# STM32U585 register map
File version: 1.4
CPU: CM33 r0p1, little endian, MPU, FPU, 4 interrupt priority bits
Registers are 32-bit, read-write, reset 0x0 unless marked. A register's access mark holds for its fields unless they carry their own. Offsets are from the block's base; [hi:lo] are bit positions.

## GTZC2_TZSC
Base 0x46023000
Same registers: SEC_GTZC2_TZSC 0x56023000
0x00 TZSC_CR — TZSC control register
  [0] LCK — lock the configuration of GTZC1_TZSC_SECCFGRx and GTZC1_TZSC_PRIVCFGRx registers until next reset
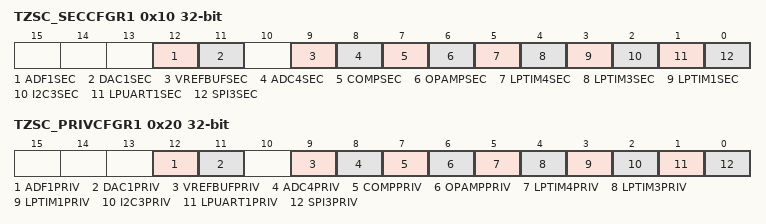
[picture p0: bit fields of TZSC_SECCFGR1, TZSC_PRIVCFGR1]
0x10 TZSC_SECCFGR1 — TZSC secure configuration register 1
  [12] ADF1SEC — secure access mode for ADF1
  [11] DAC1SEC — secure access mode for DAC1
  [9] VREFBUFSEC — secure access mode for VREFBUF
  [8] ADC4SEC — secure access mode for ADC4
  [7] COMPSEC — secure access mode for COMP
  [6] OPAMPSEC — secure access mode for OPAMP
  [5] LPTIM4SEC — secure access mode for LPTIM4
  [4] LPTIM3SEC — secure access mode for LPTIM3
  [3] LPTIM1SEC — secure access mode for LPTIM1
  [2] I2C3SEC — secure access mode for I2C3
  [1] LPUART1SEC — secure access mode for LPUART1
  [0] SPI3SEC — secure access mode for SPI3
0x20 TZSC_PRIVCFGR1 — TZSC privilege configuration register 1
  [12] ADF1PRIV — privileged access mode for ADF1
  [11] DAC1PRIV — privileged access mode for DAC1
  [9] VREFBUFPRIV — privileged access mode for VREFBUF
  [8] ADC4PRIV — privileged access mode for ADC4
  [7] COMPPRIV — privileged access mode for COMP
  [6] OPAMPPRIV — privileged access mode for OPAMP
  [5] LPTIM4PRIV — privileged access mode for LPTIM4
  [4] LPTIM3PRIV — privileged access mode for LPTIM3
  [3] LPTIM1PRIV — privileged access mode for LPTIM1
  [2] I2C3PRIV — privileged access mode for I2C3
  [1] LPUART1PRIV — privileged access mode for LPUART1
  [0] SPI3PRIV — privileged access mode for SPI3

## TIM6 — General-purpose-timers
Base 0x40001000
Same registers: TIM7 0x40001400, SEC_TIM6 0x50001000, SEC_TIM7 0x50001400
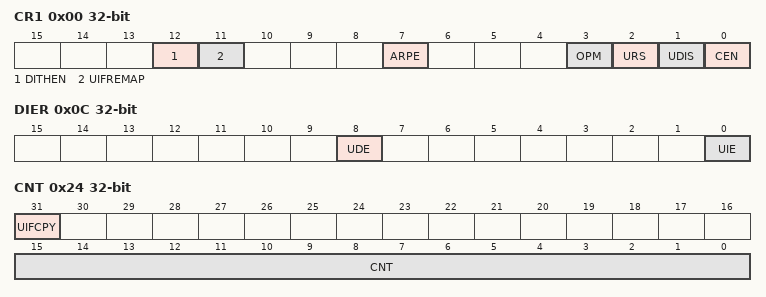
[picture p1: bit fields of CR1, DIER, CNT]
0x00 CR1 — control register 1
  [12] DITHEN — Dithering Enable
    0=Disabled (Dithering disabled); 1=Enabled (Dithering enabled)
  [11] UIFREMAP — UIF status bit remapping
    0=Disabled (No remapping. UIF status bit is not copied to TIMx_CNT register bit 31); 1=Enabled (Remapping enabled. UIF status bit is copied to TIMx_CNT register bit 31)
  [7] ARPE — Auto-reload preload enable
    0=Disabled (TIMx_APRR register is not buffered); 1=Enabled (TIMx_APRR register is buffered)
  [3] OPM — One-pulse mode
    0=Disabled (Counter is not stopped at update event); 1=Enabled (Counter stops counting at the next update event (clearing the CEN bit))
  [2] URS — Update request source
    0=AnyEvent (Any of counter overflow/underflow, setting UG, or update through slave mode, generates an update interrupt or DMA request); 1=CounterOnly (Only counter overflow/underflow generates an update interrupt or DMA request)
  [1] UDIS — Update disable
    0=Enabled (Update event enabled); 1=Disabled (Update event disabled)
  [0] CEN — Counter enable
    0=Disabled (Counter disabled); 1=Enabled (Counter enabled)
0x04 CR2 — control register 2
  [6:4] MMS — Master mode selection
    0=Reset (Use UG bit from TIMx_EGR register); 1=Enable (Use CNT bit from TIMx_CEN register); 2=Update (Use the update event)
0x0C DIER — DMA/Interrupt enable register
  [8] UDE
    0=Disabled (Update DMA request disabled); 1=Enabled (Update DMA request enabled)
  [0] UIE
    0=Disabled (Update interrupt disabled); 1=Enabled (Update interrupt enabled)
0x10 SR — status register
  [0] UIF write-0-clears
    on read: 0=NoUpdateOccurred; 1=UpdatePending (Update interrupt pending) | on write: 0=Clear flag
0x14 EGR wo — event generation register
  [0] UG
    1=Update (Re-initializes the timer counter and generates an update of the registers.)
0x24 CNT — counter
  [31] UIFCPY
    on read: 0=NoUpdateOccurred; 1=UpdatePending (Update interrupt pending)
  [15:0] CNT
0x28 PSC — prescaler
  [15:0] PSC
0x2C ARR reset 0xFFFF — auto-reload register
  [19:0] ARR
